# RL6842_IP_SVD register map
Vendor: Realtek
Registers are 32-bit, read-write, reset 0x0 unless marked. A register's access mark holds for its fields unless they carry their own. Offsets are from the block's base; [hi:lo] are bit positions; {n}, {i} and the like mark numbered series; <NAME> marks a mode.

## ECDSA_REG
Base 0x4011F000
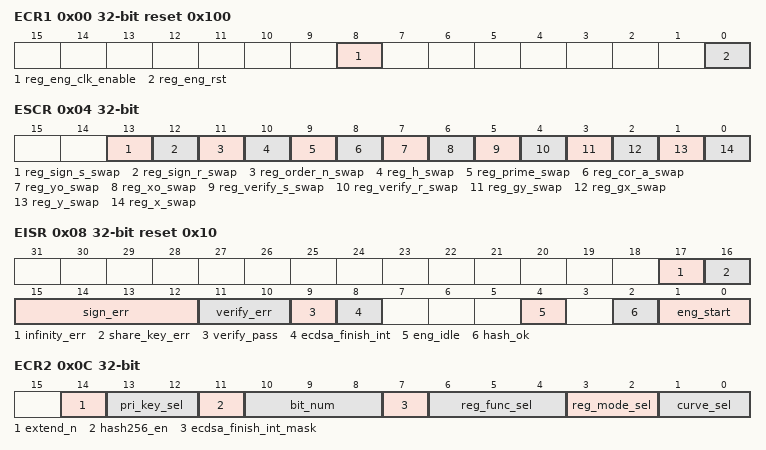
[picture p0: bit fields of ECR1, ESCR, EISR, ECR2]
0x00 ECR1 reset 0x100 — ECDSA Control Register 1
  [8] reg_eng_clk_enable — ECDSA engine clock enable signal.
  [0] reg_eng_rst — ECDSA reset. Used to reset flip-flop that are clocked by the eng_clk.
0x04 ESCR — ECDSA Swap Control Register
  [13] reg_sign_s_swap — Byte swap for eng_sign_s
  [12] reg_sign_r_swap — Byte swap for eng_sign_r
  [11] reg_order_n_swap — Byte swap for order_n
  [10] reg_h_swap — Byte swap for eng_h
  [9] reg_prime_swap — Byte swap for prime
  [8] reg_cor_a_swap — Byte swap for cor_a
  [7] reg_yo_swap — Byte swap for eng_yo
  [6] reg_xo_swap — Byte swap for eng_xo
  [5] reg_verify_s_swap — Byte swap for eng_verify_s
  [4] reg_verify_r_swap — Byte swap for eng_verify_r
  [3] reg_gy_swap — Byte swap for eng_gy
  [2] reg_gx_swap — Byte swap for eng_gx
  [1] reg_y_swap — Byte swap for eng_y
  [0] reg_x_swap — Byte swap for eng_x
0x08 EISR access per field reset 0x10 — ECDSA Interrupt Status Register
  [17] infinity_err ro — This bit indicates that the output coordinates are at infinity.
  [16] share_key_err ro — When secret_key < 1, or secret_key > (order_n-1), the bit is set to 1.
  [15:12] sign_err ro — Error message description 0001: private <1 or private > (order_n-1) 0010: (random_k % order_n) == 0 0100: r == 0 1000: s == 0
  [11:10] verify_err ro — Error message description 01: R < 1, or R > (order_n-1) 10: S < 1, or S > (order_n-1)
  [9] verify_pass ro — Verification is completed successfully.
  [8] ecdsa_finish_int rw — ECDSA interrupt status. This bit is cleaned by writing 1. If ecdsa_finish_int_mask is configured to 0, it only masks ecdsa_int trigger, ecdsa_finish_int still holds the status.
  [4] eng_idle ro — When the ECDSA is idle, the bit is set to 1.
  [2] hash_ok rw — After the calculation of SHA (m) is completed, this bit will be set to 1 by the software.
  [1:0] eng_start wo — When this bit is set to 1, ECDSA will start the operation according to the corresponding register.
0x0C ECR2 — ECDSA Control Register 2
  [14] extend_n — When this bit is set to 1, order_n will extend out of 8 bits. 001: 232-bit 010: 200-bit 011: 168-bit 100: 126-bit 101: 120-bit Others: 256-bit
  [13:12] pri_key_sel — Reserved bits.
  [11] hash256_en — If the length of the hash message exceeds 128-bit, use this function to speed up the operation.
  [10:8] bit_num — Select bit_num for correspoinding bit length, when "exten_n" is set to 0. 001: 224-bit 010: 192-bit 011: 160-bit 100: 128-bit 101: 112-bit Others: 256-bit
  [7] ecdsa_finish_int_mask — Mask ECDSA engine interrupt. When the ecdsa_finish_int = 1'b1, if ecdsa_finish_int_mask = 1'b1, then the bit masks ecdsa_int. It means that ecdsa_int = 1'b0, but the ecdsa_finish_int status still holds the value(1'b1) in EISR register.
  [6:4] reg_func_sel — The bit is used to select the operation in basic function mode. The bits are valid when reg_mode_sel[1:0] is set to 2'b11. 000: Field subtraction 001: Field division 010: Field addition 011: Field multiplication 1xx: Point addition
  [3:2] reg_mode_sel — Select operating mode 00: Verification 01: Signature 10: Scalar multiplication 11: Basic function
  [1:0] curve_sel — Select the ECC curve 00: secp256k1 01: P-256 10: Curve25519 Weierstrass 11: Others
{0x10+4i} eng_x_p{i} (i=0..7) — ENG_X_P Register {i}
  [31:0] eng_x_p{i} — Date register Verification mode: Public key x Signature mode: Private key Scalar multiplication mode: Base point x Basic function mode: Operand
{0x30+4i} eng_y_p{i} (i=0..7) — ENG_Y_P Register {i}
  [31:0] eng_y_p{i} — Date register Verification mode: Public key y Signature mode: Random k Scalar multiplication mode: Base point y Basic function mode: Operand
{0x50+4i} eng_gx_ps{i} (i=0..7) — ENG_GX_PS Register {i}
  [31:0] eng_gx_ps{i} — Because the default cur_sel[1:0] = 2'd0 (secp256k1), so these register initial values are secp256k1 setting values. Verification mode: Base point x Signature mode: Base point x Scalar multiplication mode: Base point x Basic function mode:
{0x70+4i} eng_gy_ps{i} (i=0..7) — ENG_GY_PS Register {i}
  [31:0] eng_gy_ps{i} — Because the default cur_sel[1:0] = 2'd0 (secp256k1), so these register initial values are secp256k1 setting values. Verification mode: Base point y Signature mode: Base point y Scalar multiplication mode: Base point y Basic function mode:
{0x90+4i} eng_xo_p{i} ro (i=0..7) — ENG_XO_P Register {i}
  [31:0] eng_xo_p{i} — Date register Verification mode: R_x Signature mode: Public x Scalar multiplication mode: Public x Basic function mode: Coordinate x
{0xB0+4i} eng_yo_p{i} ro (i=0..7) — ENG_YO_P Register {i}
  [31:0] eng_yo_p{i} — Date register Verification mode: R_y Signature mode: Public y Scalar multiplication mode: Public y Basic function mode: Coordinate y
{0xD0+4i} eng_sign_r_s{i} ro (i=0..7) — ENG_SIGN_R_S Register {i}
  [31:0] eng_sign_r_s{i} — Date register Verification mode: Signature mode: R Scalar multiplication mode: Basic function mode:
{0xF0+4i} eng_sign_s_s{i} ro (i=0..7) — ENG_SIGN_S_S Register {i}
  [31:0] eng_sign_s_s{i} — Date register Verification mode: Signature mode: S Scalar multiplication mode: Basic function mode:
{0x110+4i} eng_verify_r_p{i} (i=0..7) — ENG_VERIFY_R_P Register {i}
  [31:0] eng_verify_r_p{i} — Date register Verification mode: R Signature mode: Scalar multiplication mode: Basic function mode:
{0x130+4i} eng_verify_s_p{i} (i=0..7) — ENG_VERIFY_S_P Register {i}
  [31:0] eng_verify_s_p{i} — Date register Verification mode: S Signature mode: Scalar multiplication mode: Basic function mode:
{0x150+4i} eng_h_p{i} (i=0..7) — ENG_H_P Register {i}
  [31:0] eng_h_p{i} — ECDSA "hash" parameter Verification mode: Hash Signature mode: Hash Scalar multiplication mode: Private key Basic function mode:
{0x170+4i} cor_a_p{i} (i=0..7) — COR_A_P Register {i}
  [31:0] cor_a_p{i} — ECDSA "a" parameter Verification mode: cor_a Signature mode: cor_a Scalar multiplication mode: cor_a Basic function mode: cor_a
{0x190+4i} prime_p{i} (i=0..7) — Prime_P Register {i}
  [31:0] prime_p{i} — Because the default cur_sel[1:0] = 2'd0 (secp256k1), so these registers' initial values are secp256k1 setting values. ECDSA "prime" parameter Verification mode: Prime Signature mode: Prime Scalar multiplication mode: Prime Basic function mode: Prime
{0x1B0+4i} order_n_p{i} (i=0..7) — Order_N_P Register {i}
  [31:0] order_n_p{i} — Because the default cur_sel[1:0] = 2'd0 (secp256k1), so these registers' initial values are secp256k1 setting values. ECDSA "prime" parameter Verification mode: order_n Signature mode: order_n Scalar multiplication mode: order_n Basic function mode: order_n
0x200 ecdsa_dbg_o ro — ECDSA Debug Output Register
  [31:0] ecdsa_dbg_o — Debug singnals
